# CM41x_M4 register map
Vendor: Analog Devices; Series: CM41x_M4; File version: 1p0
CPU: CM4 r0p1, little endian, MPU, FPU, 4 interrupt priority bits
Registers are 32-bit, read-write, reset 0x0 unless marked. A register's access mark holds for its fields unless they carry their own. Offsets are from the block's base; [hi:lo] are bit positions.

## CNT0 — CNT
Base 0x40022000
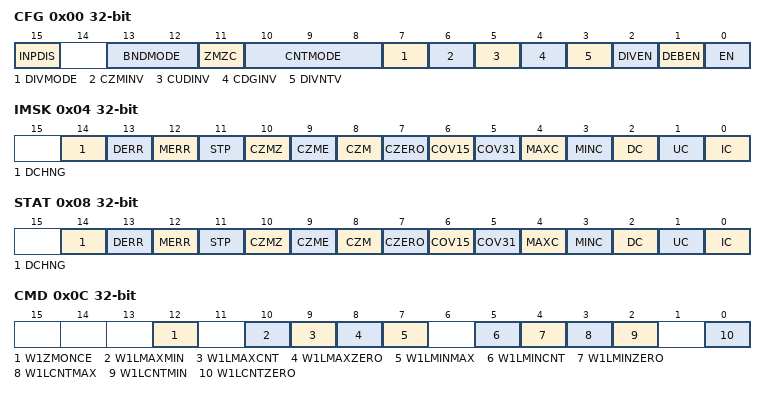
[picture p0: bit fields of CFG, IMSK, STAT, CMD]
0x00 CFG — Configuration Register
  [15] INPDIS — CUD and CDG Pin Input Disable
    0=NO_INPDIS (Enable); 1=INPDIS (Pin Input Disable)
  [13:12] BNDMODE — Boundary Register Mode
    0=BNDMODE_BNDCOMP (BND_COMP.); 1=BNDMODE_BINENC (BND_ZERO.); 2=BNDMODE_BNDCAPT (BND_CAPT.); 3=BNDMODE_BNDAEXT (BND_AEXT.)
  [11] ZMZC — CZM Zeros Counter Enable
    0=ZMZC_DIS (Disable); 1=ZMZC_EN (Enable)
  [10:8] CNTMODE — Counter Operating Mode
    0=CNTMODE_QUADENC (QUAD_ENC.); 1=CNTMODE_BINENC (BIN_ENC.); 2=CNTMODE_UDCNT (UD_CNT.); 4=CNTMODE_DIRCNT (DIR_CNT.); 5=CNTMODE_DIRTMR (DIR_TMR.)
  [7] DIVMODE — Divider Mode
  [6] CZMINV — CZM Pin Polarity Invert
    0=CZMINV_AHI (Active High, Rising Edge); 1=CZMINV_ALO (Active Low, Falling Edge)
  [5] CUDINV — CUD Pin Polarity Invert
    0=CUDINV_AHI (Active High, Rising Edge); 1=CUDINV_ALO (Active Low, Falling Edge)
  [4] CDGINV — CDG Pin Polarity Invert
    0=CDGINV_AHI (Active High, Rising Edge); 1=CDGINV_ALO (Active Low, Falling Edge)
  [3] DIVNTV — Non-debounced Inputs to Divider Enable
  [2] DIVEN — Divider Enable
  [1] DEBEN — Debounce Enable
    0=DEBDIS (Disable); 1=DEBEN (Enable)
  [0] EN — Counter Enable
    0=CNTDIS (Counter Disable); 1=CNTEN (Counter Enable)
0x04 IMSK — Interrupt Mask Register
  [14] DCHNG — Direction Change Interrupt Enable
  [13] DERR — Direction Error Interrupt Enable
  [12] MERR — M Value Programming Error Interrupt Enable
  [11] STP — Stop Detect Interrupt Enable
  [10] CZMZ — Counter Zeroed by Zero Marker Interrupt Enable
    0=CZMZ_MSK (Mask Interrupt); 1=CZMZ_UMSK (Unmask Interrupt)
  [9] CZME — Zero Marker Error Interrupt Enable
    0=CZME_MSK (Mask Interrupt); 1=CZME_UMSK (Unmask Interrupt)
  [8] CZM — CZM Pin/Pushbutton Interrupt Enable
    0=CZM_MSK (Mask Interrupt); 1=CZM_UMSK (Unmask Interrupt)
  [7] CZERO — CNT_CNTR Counts To Zero Interrupt Enable
    0=CZERO_MSK (Mask Interrupt); 1=CZERO_UMSK (Unmask Interrupt)
  [6] COV15 — Bit 15 Overflow Interrupt Enable
    0=COV15_MSK (Mask Interrupt); 1=COV15_UMSK (Unmask Interrupt)
  [5] COV31 — Bit 31 Overflow Interrupt Enable
    0=COV31_MSK (Mask Interrupt); 1=COV31_UMSK (Unmask Interrupt)
  [4] MAXC — Max Count Interrupt Enable
    0=MAXC_MSK (Mask Interrupt); 1=MAXC_UMSK (Unmask Interrupt)
  [3] MINC — Min Count Interrupt Enable
    0=MINC_MSK (Mask Interrupt); 1=MINC_UMSK (Unmask Interrupt)
  [2] DC — Downcount Interrupt Enable
    0=DC_MSK (Mask Interrupt); 1=DC_UMSK (Unmask Interrupt)
  [1] UC — Upcount Interrupt Enable
    0=UC_MSK (Mask Interrupt); 1=UC_UMSK (Unmask Interrupt)
  [0] IC — Illegal Gray/Binary Code Interrupt Enable
    0=IC_MSK (Mask Interrupt); 1=IC_UMSK (Unmask Interrupt)
0x08 STAT — Status Register
  [14] DCHNG range 0x00000000..0x00000001 — Direction Change Interrupt Enable
  [13] DERR range 0x00000000..0x00000001 — Direction Error Interrupt
  [12] MERR range 0x00000000..0x00000001 — M Value Programming Error Interrupt
  [11] STP range 0x00000000..0x00000001 — Stop Detect Interrupt
  [10] CZMZ — Counter Zeroed By Zero Marker Interrupt
  [9] CZME — Zero Marker Error Interrupt
  [8] CZM — CZM Pin/Pushbutton Interrupt
  [7] CZERO — CNT_CNTR Counts To Zero Interrupt
  [6] COV15 — Bit 15 Overflow Interrupt
  [5] COV31 — Bit 31 Overflow Interrupt
  [4] MAXC — Max Count Interrupt
  [3] MINC — Min Count Interrupt
  [2] DC — Down Count Interrupt
  [1] UC range 0x00000000..0x00000001 — Up Count Interrupt
  [0] IC — Illegal Gray/Binary Code Interrupt
0x0C CMD — Command Register
  [12] W1ZMONCE range 0x00000000..0x00000001 — Write 1 Zero Marker Clear Once Enable
  [10] W1LMAXMIN range 0x00000000..0x00000001 — Write 1 MAX Copy from MIN
  [9] W1LMAXCNT range 0x00000000..0x00000001 — Write 1 MAX Capture from CNTR
  [8] W1LMAXZERO range 0x00000000..0x00000001 — Write 1 MAX to Zero
  [7] W1LMINMAX range 0x00000000..0x00000001 — Write 1 MIN Copy from MAX
  [5] W1LMINCNT range 0x00000000..0x00000001 — Write 1 MIN Capture from CNTR
  [4] W1LMINZERO range 0x00000000..0x00000001 — Write 1 MIN to Zero
  [3] W1LCNTMAX range 0x00000000..0x00000001 — Write 1 CNTR Load from MAX
  [2] W1LCNTMIN range 0x00000000..0x00000001 — Write 1 CNTR Load from MIN
  [0] W1LCNTZERO range 0x00000000..0x00000001 — Write 1 CNTR to Zero
0x10 DEBNCE — Debounce Register
  [4:0] DPRESCALE — Debounce Prescale
0x14 CNTR — Counter Register
  [31:0] VALUE range 0x00000000..0xFFFFFFFF — CNTR Value
0x18 MAX — Maximum Count Register
  [31:0] VALUE range 0x00000000..0xFFFFFFFF — MAX Value
0x1C MIN — Minimum Count Register
  [31:0] VALUE range 0x00000000..0xFFFFFFFF — MIN Value
0x20 MDIV — M Value for Divider
  [15:0] MDIV range 0x00000000..0x0000FFFF
0x24 NDIV — N Value for Divider
  [15:0] NDIV range 0x00000000..0x0000FFFF
